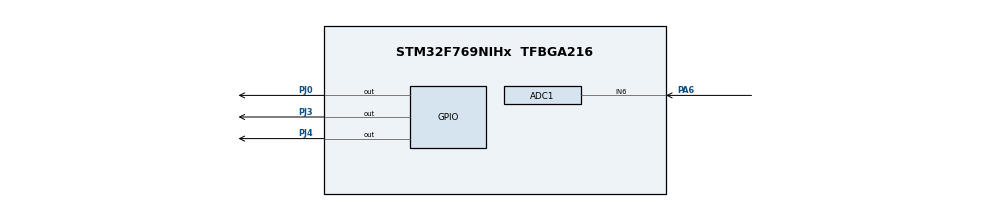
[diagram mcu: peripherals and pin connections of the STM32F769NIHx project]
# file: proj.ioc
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ADC1.Channel-0\#ChannelRegularConversion=ADC_CHANNEL_6
ADC1.NbrOfConversionFlag=1
ADC1.Rank-0\#ChannelRegularConversion=1
ADC1.SamplingTime-0\#ChannelRegularConversion=ADC_SAMPLETIME_3CYCLES
ADC1.master=1
Mcu.Family=STM32F7
Mcu.Name=STM32F769NIHx
Mcu.Package=TFBGA216
NVIC.ADC_IRQn=true\:0\:0\:false\:false\:true\:true\:true
NVIC.PriorityGroup=NVIC_PRIORITYGROUP_4
PA6.Signal=SharedAnalog_PA6
PJ0.Signal=GPIO_Output
PJ3.Signal=GPIO_Output
PJ4.Signal=GPIO_Output
ProjectManager.HeapSize=0x200
ProjectManager.StackSize=0x400
ProjectManager.TargetToolchain=STM32CubeIDE
RCC.HSE_VALUE=25000000
RCC.HSI_VALUE=16000000
RCC.LSE_VALUE=32768
RCC.USBFreq_Value=96000000
RCC.VCOOutputFreq_Value=192000000
SH.SharedAnalog_PA6.0=GPIO_Analog
SH.SharedAnalog_PA6.1=ADC1_IN6,IN6
board=custom

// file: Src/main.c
/* USER CODE BEGIN Header */
/**
  ******************************************************************************
  * @file           : main.c
  * @brief          : Main program body
  ******************************************************************************
  * @attention
  *
  * <h2><center>&copy; Copyright (c) 2019 STMicroelectronics.
  * All rights reserved.</center></h2>
  *
  * This software component is licensed by ST under BSD 3-Clause license,
  * the "License"; You may not use this file except in compliance with the
  * License. You may obtain a copy of the License at:
  *                        opensource.org/licenses/BSD-3-Clause
  *
  ******************************************************************************
  */
/* USER CODE END Header */

#include "main.h"

ADC_HandleTypeDef hadc1;

void SystemClock_Config(void);
static void MX_GPIO_Init(void);
static void MX_ADC1_Init(void);

int main(void)
{

  /* MCU Configuration--------------------------------------------------------*/

  /* Reset of all peripherals, Initializes the Flash interface and the Systick. */
  HAL_Init();

  /* Configure the system clock */
  SystemClock_Config();

  /* Initialize all configured peripherals */
  MX_GPIO_Init();
  MX_ADC1_Init();

  /* Infinite loop */
  /* USER CODE BEGIN WHILE */
  uint32_t g_ADCValue;
  ADC_HandleTypeDef g_AdcHandle;
  uint32_t prev_value = 0;
  while (1)
  {
    /* USER CODE END WHILE */
	  HAL_ADC_Start(&hadc1);
	  HAL_ADC_PollForConversion(&hadc1, 100);
	  g_ADCValue = HAL_ADC_GetValue(&hadc1);
	  if(prev_value - g_ADCValue > 10){
		  if(g_ADCValue <= 1240){
		     	  HAL_GPIO_WritePin(GPIOJ,GPIO_PIN_4, GPIO_PIN_SET);
		 	 	  HAL_GPIO_WritePin(GPIOJ,GPIO_PIN_3, GPIO_PIN_RESET);
		 	 	  HAL_GPIO_WritePin(GPIOJ,GPIO_PIN_0, GPIO_PIN_RESET);
		  } else if(g_ADCValue > 1240 && g_ADCValue <= 2500){
		     	  HAL_GPIO_WritePin(GPIOJ,GPIO_PIN_4, GPIO_PIN_RESET);
		 		  HAL_GPIO_WritePin(GPIOJ,GPIO_PIN_3, GPIO_PIN_SET);
		 		  HAL_GPIO_WritePin(GPIOJ,GPIO_PIN_0, GPIO_PIN_RESET);
	      } else if(g_ADCValue > 2500){
		     	  HAL_GPIO_WritePin(GPIOJ,GPIO_PIN_4, GPIO_PIN_RESET);
		 		  HAL_GPIO_WritePin(GPIOJ,GPIO_PIN_3, GPIO_PIN_RESET);
		 		  HAL_GPIO_WritePin(GPIOJ,GPIO_PIN_0, GPIO_PIN_SET);
	      }
	  } else {
		  if(g_ADCValue <= 2000){
		     	  HAL_GPIO_WritePin(GPIOJ,GPIO_PIN_4, GPIO_PIN_SET);
		 	 	  HAL_GPIO_WritePin(GPIOJ,GPIO_PIN_3, GPIO_PIN_RESET);
		 	 	  HAL_GPIO_WritePin(GPIOJ,GPIO_PIN_0, GPIO_PIN_RESET);
		  } else if(g_ADCValue > 2000 && g_ADCValue <= 3200){
		     	  HAL_GPIO_WritePin(GPIOJ,GPIO_PIN_4, GPIO_PIN_RESET);
		 		  HAL_GPIO_WritePin(GPIOJ,GPIO_PIN_3, GPIO_PIN_SET);
		 		  HAL_GPIO_WritePin(GPIOJ,GPIO_PIN_0, GPIO_PIN_RESET);
	      } else if(g_ADCValue > 3200){
		     	  HAL_GPIO_WritePin(GPIOJ,GPIO_PIN_4, GPIO_PIN_RESET);
		 		  HAL_GPIO_WritePin(GPIOJ,GPIO_PIN_3, GPIO_PIN_RESET);
		 		  HAL_GPIO_WritePin(GPIOJ,GPIO_PIN_0, GPIO_PIN_SET);
	      }
	  }
	  prev_value = g_ADCValue;
	  HAL_Delay(100);
      HAL_ADC_Stop(&hadc1);
  }
}

void SystemClock_Config(void)
{
  RCC_OscInitTypeDef RCC_OscInitStruct = {0};
  RCC_ClkInitTypeDef RCC_ClkInitStruct = {0};

  /** Configure the main internal regulator output voltage
  */
  __HAL_RCC_PWR_CLK_ENABLE();
  __HAL_PWR_VOLTAGESCALING_CONFIG(PWR_REGULATOR_VOLTAGE_SCALE3);
  /** Initializes the CPU, AHB and APB busses clocks
  */
  RCC_OscInitStruct.OscillatorType = RCC_OSCILLATORTYPE_HSI;
  RCC_OscInitStruct.HSIState = RCC_HSI_ON;
  RCC_OscInitStruct.HSICalibrationValue = RCC_HSICALIBRATION_DEFAULT;
  RCC_OscInitStruct.PLL.PLLState = RCC_PLL_NONE;
  if (HAL_RCC_OscConfig(&RCC_OscInitStruct) != HAL_OK)
  {
    Error_Handler();
  }
  /** Initializes the CPU, AHB and APB busses clocks
  */
  RCC_ClkInitStruct.ClockType = RCC_CLOCKTYPE_HCLK|RCC_CLOCKTYPE_SYSCLK
                              |RCC_CLOCKTYPE_PCLK1|RCC_CLOCKTYPE_PCLK2;
  RCC_ClkInitStruct.SYSCLKSource = RCC_SYSCLKSOURCE_HSI;
  RCC_ClkInitStruct.AHBCLKDivider = RCC_SYSCLK_DIV1;
  RCC_ClkInitStruct.APB1CLKDivider = RCC_HCLK_DIV1;
  RCC_ClkInitStruct.APB2CLKDivider = RCC_HCLK_DIV1;

  if (HAL_RCC_ClockConfig(&RCC_ClkInitStruct, FLASH_LATENCY_0) != HAL_OK)
  {
    Error_Handler();
  }
}

static void MX_ADC1_Init(void)
{

  ADC_ChannelConfTypeDef sConfig = {0};

  /** Configure the global features of the ADC (Clock, Resolution, Data Alignment and number of conversion)
  */
  hadc1.Instance = ADC1;
  hadc1.Init.ClockPrescaler = ADC_CLOCK_SYNC_PCLK_DIV2;
  hadc1.Init.Resolution = ADC_RESOLUTION_12B;
  hadc1.Init.ScanConvMode = DISABLE;
  hadc1.Init.ContinuousConvMode = DISABLE;
  hadc1.Init.DiscontinuousConvMode = DISABLE;
  hadc1.Init.ExternalTrigConvEdge = ADC_EXTERNALTRIGCONVEDGE_NONE;
  hadc1.Init.ExternalTrigConv = ADC_SOFTWARE_START;
  hadc1.Init.DataAlign = ADC_DATAALIGN_RIGHT;
  hadc1.Init.NbrOfConversion = 1;
  hadc1.Init.DMAContinuousRequests = DISABLE;
  hadc1.Init.EOCSelection = ADC_EOC_SINGLE_CONV;
  if (HAL_ADC_Init(&hadc1) != HAL_OK)
  {
    Error_Handler();
  }
  /** Configure for the selected ADC regular channel its corresponding rank in the sequencer and its sample time.
  */
  sConfig.Channel = ADC_CHANNEL_6;
  sConfig.Rank = ADC_REGULAR_RANK_1;
  sConfig.SamplingTime = ADC_SAMPLETIME_3CYCLES;
  if (HAL_ADC_ConfigChannel(&hadc1, &sConfig) != HAL_OK)
  {
    Error_Handler();
  }

}

static void MX_GPIO_Init(void)
{
  GPIO_InitTypeDef GPIO_InitStruct = {0};

  /* GPIO Ports Clock Enable */
  __HAL_RCC_GPIOJ_CLK_ENABLE();
  __HAL_RCC_GPIOA_CLK_ENABLE();

  /*Configure GPIO pin Output Level */
  HAL_GPIO_WritePin(GPIOJ, GPIO_PIN_4|GPIO_PIN_3|GPIO_PIN_0, GPIO_PIN_RESET);

  /*Configure GPIO pins : PJ4 PJ3 PJ0 */
  GPIO_InitStruct.Pin = GPIO_PIN_4|GPIO_PIN_3|GPIO_PIN_0;
  GPIO_InitStruct.Mode = GPIO_MODE_OUTPUT_PP;
  GPIO_InitStruct.Pull = GPIO_NOPULL;
  GPIO_InitStruct.Speed = GPIO_SPEED_FREQ_LOW;
  HAL_GPIO_Init(GPIOJ, &GPIO_InitStruct);

  /*Configure GPIO pin : PA6 */
  GPIO_InitStruct.Pin = GPIO_PIN_6;
  GPIO_InitStruct.Mode = GPIO_MODE_ANALOG;
  GPIO_InitStruct.Pull = GPIO_NOPULL;
  HAL_GPIO_Init(GPIOA, &GPIO_InitStruct);

}

void Error_Handler(void)
{
}

/************************ (C) COPYRIGHT STMicroelectronics *****END OF FILE****/
